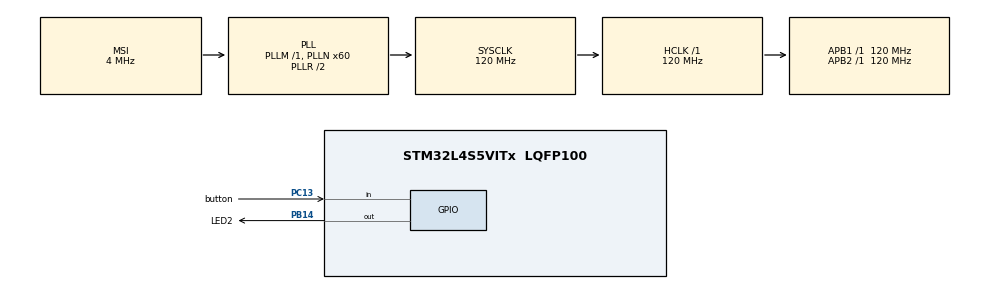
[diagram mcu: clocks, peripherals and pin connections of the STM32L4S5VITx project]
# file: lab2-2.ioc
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ADC1.Channel-1\#ChannelRegularConversion=ADC_CHANNEL_TEMPSENSOR
ADC1.NbrOfConversionFlag=1
ADC1.OffsetNumber-1\#ChannelRegularConversion=ADC_OFFSET_NONE
ADC1.Rank-1\#ChannelRegularConversion=1
ADC1.SamplingTime-1\#ChannelRegularConversion=ADC_SAMPLETIME_12CYCLES_5
ADC1.master=1
Mcu.Family=STM32L4
Mcu.Name=STM32L4S5VITx
Mcu.Package=LQFP100
NVIC.PriorityGroup=NVIC_PRIORITYGROUP_4
PB14.GPIO_Label=LED2
PB14.Signal=GPIO_Output
PC13.GPIO_Label=button
PC13.Signal=GPIO_Input
ProjectManager.HeapSize=0x200
ProjectManager.StackSize=0x400
ProjectManager.TargetToolchain=STM32CubeIDE
RCC.ADCFreq_Value=48000000
RCC.AHBFreq_Value=120000000
RCC.APB1Freq_Value=120000000
RCC.APB1TimFreq_Value=120000000
RCC.APB2Freq_Value=120000000
RCC.APB2TimFreq_Value=120000000
RCC.CortexFreq_Value=120000000
RCC.HCLKFreq_Value=120000000
RCC.HSE_VALUE=8000000
RCC.HSI48_VALUE=48000000
RCC.HSI_VALUE=16000000
RCC.LSE_VALUE=32768
RCC.MSI_VALUE=4000000
RCC.PLLN=60
RCC.PLLSAI1N=24
RCC.SYSCLKFreq_VALUE=120000000
RCC.SYSCLKSource=RCC_SYSCLKSOURCE_PLLCLK
RCC.USBFreq_Value=48000000
RCC.VCOOutputFreq_Value=240000000
VP_ADC1_TempSens_Input.Mode=IN-TempSens
VP_ADC1_Vref_Input.Mode=IN-Vrefint
board=B-L4S5I-IOT01A

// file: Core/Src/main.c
/* USER CODE BEGIN Header */
/**
  ******************************************************************************
  * @file           : main.c
  * @brief          : Main program body
  ******************************************************************************
  * @attention
  *
  * Copyright (c) 2024 STMicroelectronics.
  * All rights reserved.
  *
  * This software is licensed under terms that can be found in the LICENSE file
  * in the root directory of this software component.
  * If no LICENSE file comes with this software, it is provided AS-IS.
  *
  ******************************************************************************
  */
/* USER CODE END Header */
#include "main.h"

/* USER CODE BEGIN PD */
char adc_mode = 2;//Boolean to have chip read voltage first and then let user press on button to chose whether voltage or temp is read
uint32_t vdda_voltage;//variable to hold voltage reference
/* USER CODE END PD */

ADC_HandleTypeDef hadc1;

void SystemClock_Config(void);
static void MX_GPIO_Init(void);
static void MX_ADC1_Init(void);

int main(void)
{

  /* MCU Configuration--------------------------------------------------------*/

  /* Reset of all peripherals, Initializes the Flash interface and the Systick. */
  HAL_Init();

  /* Configure the system clock */
  SystemClock_Config();

  /* Initialize all configured peripherals */
  MX_GPIO_Init();
  MX_ADC1_Init();

  /* Infinite loop */
  while (1)
  {

    /* USER CODE BEGIN 3 */

	  //VOLTAGE
	  if(adc_mode == 0 || adc_mode == 2){
		  HAL_GPIO_WritePin(LED2_GPIO_Port, LED2_Pin, GPIO_PIN_SET);//LED turned on when reading voltage

		  //configuration of channel for reading reference voltage
		  ADC_ChannelConfTypeDef channel_config = {.Channel = ADC_CHANNEL_VREFINT, .Rank = ADC_REGULAR_RANK_1,
				  .SamplingTime=ADC_SAMPLETIME_12CYCLES_5, .SingleDiff = ADC_SINGLE_ENDED, .OffsetNumber = ADC_OFFSET_NONE, .Offset=0
		  };//12.5 is the sampling time corresponding to chosen resolution of 12

		  if(HAL_ADC_ConfigChannel(&hadc1, &channel_config) != HAL_OK){
			  return -1;
		  }
		  HAL_ADC_Start(&hadc1);//starting ADC

		  HAL_ADC_PollForConversion(&hadc1, 0xFFFF);//poll and wait for ADC conversion to complete
		  uint32_t adcValue = HAL_ADC_GetValue(&hadc1);
		  HAL_ADC_Stop(&hadc1);

		  //we use the HAL ADC function to calculate reference voltage depending on resolution chosen
		  vdda_voltage = __HAL_ADC_CALC_VREFANALOG_VOLTAGE(adcValue, ADC_RESOLUTION_12B);
	  }else{

		  //TEMPERATURE
		  HAL_GPIO_WritePin(LED2_GPIO_Port, LED2_Pin, GPIO_PIN_RESET);//LED turned off when reading temperature

		  //configuration of channel for reading temperature
		  ADC_ChannelConfTypeDef channel_config2 = {.Channel = ADC_CHANNEL_TEMPSENSOR, .Rank = ADC_REGULAR_RANK_1,
				  .SamplingTime=ADC_SAMPLETIME_12CYCLES_5, .SingleDiff = ADC_SINGLE_ENDED, .OffsetNumber = ADC_OFFSET_NONE, .Offset=0
			  };//12.5 is the sampling time corresponding to chosen resolution of 12

		  if(HAL_ADC_ConfigChannel(&hadc1, &channel_config2) != HAL_OK){
				  return -1;
		  }
		  HAL_ADC_Start(&hadc1);//starting ADC

		  HAL_ADC_PollForConversion(&hadc1, 0xFFFF);//poll and wait for ADC conversion to complete
		  uint32_t adcValue = HAL_ADC_GetValue(&hadc1);
		  HAL_ADC_Stop(&hadc1);

		  //we use the HAL ADC function to calculate temperature depending on resolution chosen (manual computation done in comment below)
		  int32_t Temperature = __HAL_ADC_CALC_TEMPERATURE(vdda_voltage, adcValue,ADC_RESOLUTION_12B);
		  float V_REF = 3.3f;

		  //temperature code done with conversion (COMMENT FOR REPORT)
		  /*
		  float V_30 = 0.76f;           // Voltage at 30°C
		  float Avg_Slope = 2.5f / 1000;

		  float V_Sense = (adcValue * V_REF) / 4096.0f; // dividing by 4096 because of 12-bits resolution of ADC
	  	  float temperature = ((V_Sense - V_30) / Avg_Slope) + 30.0f;*/
	  }

	  char button_status= HAL_GPIO_ReadPin(button_GPIO_Port, button_Pin);//reading whether button is pressed or not
	  if(button_status== 0){
		  adc_mode = 0;//if button is pressed, do voltage reading
	  }else{
		  adc_mode = 1;//if button not pressed, do temperature reading
	  }
  }
  /* USER CODE END 3 */
}

void SystemClock_Config(void)
{
  RCC_OscInitTypeDef RCC_OscInitStruct = {0};
  RCC_ClkInitTypeDef RCC_ClkInitStruct = {0};

  /** Configure the main internal regulator output voltage
  */
  if (HAL_PWREx_ControlVoltageScaling(PWR_REGULATOR_VOLTAGE_SCALE1_BOOST) != HAL_OK)
  {
    Error_Handler();
  }

  /** Initializes the RCC Oscillators according to the specified parameters
  * in the RCC_OscInitTypeDef structure.
  */
  RCC_OscInitStruct.OscillatorType = RCC_OSCILLATORTYPE_MSI;
  RCC_OscInitStruct.MSIState = RCC_MSI_ON;
  RCC_OscInitStruct.MSICalibrationValue = 0;
  RCC_OscInitStruct.MSIClockRange = RCC_MSIRANGE_6;
  RCC_OscInitStruct.PLL.PLLState = RCC_PLL_ON;
  RCC_OscInitStruct.PLL.PLLSource = RCC_PLLSOURCE_MSI;
  RCC_OscInitStruct.PLL.PLLM = 1;
  RCC_OscInitStruct.PLL.PLLN = 60;
  RCC_OscInitStruct.PLL.PLLP = RCC_PLLP_DIV2;
  RCC_OscInitStruct.PLL.PLLQ = RCC_PLLQ_DIV2;
  RCC_OscInitStruct.PLL.PLLR = RCC_PLLR_DIV2;
  if (HAL_RCC_OscConfig(&RCC_OscInitStruct) != HAL_OK)
  {
    Error_Handler();
  }

  /** Initializes the CPU, AHB and APB buses clocks
  */
  RCC_ClkInitStruct.ClockType = RCC_CLOCKTYPE_HCLK|RCC_CLOCKTYPE_SYSCLK
                              |RCC_CLOCKTYPE_PCLK1|RCC_CLOCKTYPE_PCLK2;
  RCC_ClkInitStruct.SYSCLKSource = RCC_SYSCLKSOURCE_PLLCLK;
  RCC_ClkInitStruct.AHBCLKDivider = RCC_SYSCLK_DIV1;
  RCC_ClkInitStruct.APB1CLKDivider = RCC_HCLK_DIV1;
  RCC_ClkInitStruct.APB2CLKDivider = RCC_HCLK_DIV1;

  if (HAL_RCC_ClockConfig(&RCC_ClkInitStruct, FLASH_LATENCY_5) != HAL_OK)
  {
    Error_Handler();
  }
}

static void MX_ADC1_Init(void)
{

  ADC_ChannelConfTypeDef sConfig = {0};

  /** Common config
  */
  hadc1.Instance = ADC1;
  hadc1.Init.ClockPrescaler = ADC_CLOCK_ASYNC_DIV1;
  hadc1.Init.Resolution = ADC_RESOLUTION_12B;
  hadc1.Init.DataAlign = ADC_DATAALIGN_RIGHT;
  hadc1.Init.ScanConvMode = ADC_SCAN_DISABLE;
  hadc1.Init.EOCSelection = ADC_EOC_SINGLE_CONV;
  hadc1.Init.LowPowerAutoWait = DISABLE;
  hadc1.Init.ContinuousConvMode = DISABLE;
  hadc1.Init.NbrOfConversion = 1;
  hadc1.Init.DiscontinuousConvMode = DISABLE;
  hadc1.Init.ExternalTrigConv = ADC_SOFTWARE_START;
  hadc1.Init.ExternalTrigConvEdge = ADC_EXTERNALTRIGCONVEDGE_NONE;
  hadc1.Init.DMAContinuousRequests = DISABLE;
  hadc1.Init.Overrun = ADC_OVR_DATA_PRESERVED;
  hadc1.Init.OversamplingMode = DISABLE;
  if (HAL_ADC_Init(&hadc1) != HAL_OK)
  {
    Error_Handler();
  }

  /** Configure Regular Channel
  */
  sConfig.Channel = ADC_CHANNEL_TEMPSENSOR;
  sConfig.Rank = ADC_REGULAR_RANK_1;
  sConfig.SamplingTime = ADC_SAMPLETIME_12CYCLES_5;
  sConfig.SingleDiff = ADC_SINGLE_ENDED;
  sConfig.OffsetNumber = ADC_OFFSET_NONE;
  sConfig.Offset = 0;
  if (HAL_ADC_ConfigChannel(&hadc1, &sConfig) != HAL_OK)
  {
    Error_Handler();
  }

}

static void MX_GPIO_Init(void)
{
  GPIO_InitTypeDef GPIO_InitStruct = {0};

  /* GPIO Ports Clock Enable */
  __HAL_RCC_GPIOC_CLK_ENABLE();
  __HAL_RCC_GPIOB_CLK_ENABLE();

  /*Configure GPIO pin Output Level */
  HAL_GPIO_WritePin(LED2_GPIO_Port, LED2_Pin, GPIO_PIN_RESET);

  /*Configure GPIO pin : button_Pin */
  GPIO_InitStruct.Pin = button_Pin;
  GPIO_InitStruct.Mode = GPIO_MODE_INPUT;
  GPIO_InitStruct.Pull = GPIO_NOPULL;
  HAL_GPIO_Init(button_GPIO_Port, &GPIO_InitStruct);

  /*Configure GPIO pin : LED2_Pin */
  GPIO_InitStruct.Pin = LED2_Pin;
  GPIO_InitStruct.Mode = GPIO_MODE_OUTPUT_PP;
  GPIO_InitStruct.Pull = GPIO_NOPULL;
  GPIO_InitStruct.Speed = GPIO_SPEED_FREQ_LOW;
  HAL_GPIO_Init(LED2_GPIO_Port, &GPIO_InitStruct);

}

void Error_Handler(void)
{
  __disable_irq();
  while (1)
  {
  }
}
